AUTOSAR XML (schema 00050)
package /Components
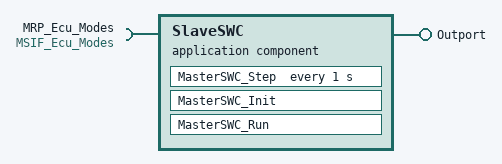
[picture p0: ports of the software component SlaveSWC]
  application sw component type SlaveSWC
    provide port Outport: nonqueued-sender-com-spec{data-element=Outport, init-value=0}, provided-interface=Outport
    require port MRP_Ecu_Modes: required-interface=MSIF_Ecu_Modes
    behavior MasterSWC_IB: data-type-mapping=MasterSWCDataTypeMappingsSet, handle-termination-and-restart=NO-SUPPORT
      timing event Event: start-on-event=MasterSWC_Step, period=1
      swc mode switch event Event_Run: start-on-event=MasterSWC_Run, activation=ON-ENTRY, mode=MRP_Ecu_Modes.MG_Ecu_Modes.INIT
      runnable MasterSWC_Step: mode-access-point=MRP_Ecu_Modes.MG_Ecu_Modes
        data-write-access:
          access OUT_Outport_Outport: accessed-variable=Outport.Outport
      runnable MasterSWC_Init
        data-write-access:
          access OUT_Outport_Outport: accessed-variable=Outport.Outport
      runnable MasterSWC_Run
